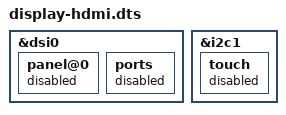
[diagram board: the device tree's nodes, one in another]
/dts-v1/;
/plugin/;

/ {
	fragment@0 {
		target = <&dsi0>;
		__overlay__ {
			panel@0 {
				status = "disabled";
			};
			ports {
				status = "disabled";
			};
		};
	};

	fragment@1 {
		target = <&i2c1>;
		__overlay__ {
			touch {
				status = "disabled";
			};
		};
	};
};
